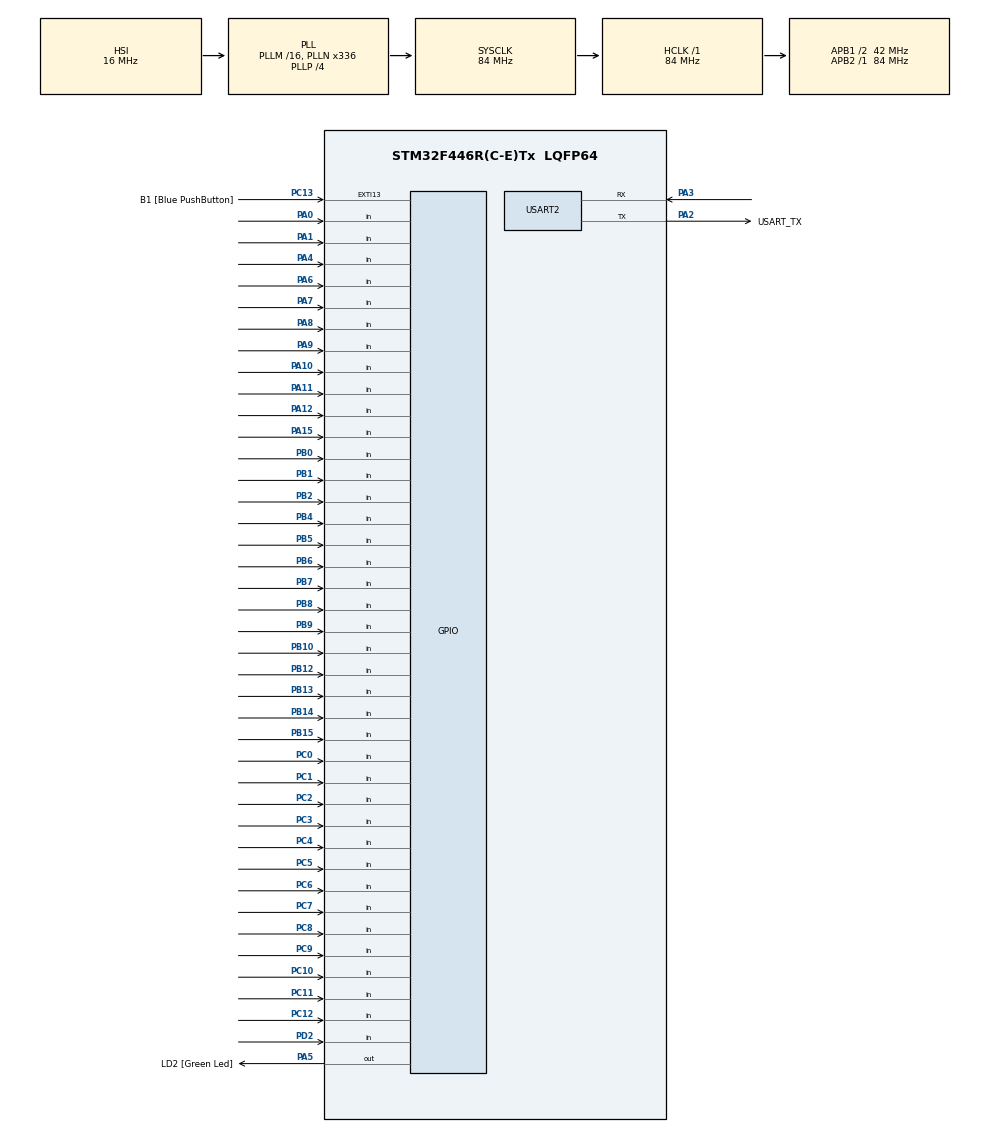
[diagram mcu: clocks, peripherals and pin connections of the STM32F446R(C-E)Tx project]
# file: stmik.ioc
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Mcu.Family=STM32F4
Mcu.Name=STM32F446R(C-E)Tx
Mcu.Package=LQFP64
NVIC.PriorityGroup=NVIC_PRIORITYGROUP_0
NVIC.USART2_IRQn=true\:0\:0\:false\:false\:true\:true\:true
PA0-WKUP.Signal=GPIO_Input
PA1.Signal=GPIO_Input
PA10.Signal=GPIO_Input
PA11.Signal=GPIO_Input
PA12.Signal=GPIO_Input
PA13.GPIO_Label=TMS
PA13.Signal=SYS_JTMS-SWDIO
PA14.GPIO_Label=TCK
PA14.Signal=SYS_JTCK-SWCLK
PA15.Signal=GPIO_Input
PA2.GPIO_Label=USART_TX
PA2.Mode=Asynchronous
PA2.Signal=USART2_TX
PA3.Mode=Asynchronous
PA3.Signal=USART2_RX
PA4.Signal=GPIO_Input
PA5.GPIO_Label=LD2 [Green Led]
PA5.Signal=GPIO_Output
PA6.Signal=GPIO_Input
PA7.Signal=GPIO_Input
PA8.Signal=GPIO_Input
PA9.Signal=GPIO_Input
PB0.Signal=GPIO_Input
PB1.Signal=GPIO_Input
PB10.Signal=GPIO_Input
PB12.Signal=GPIO_Input
PB13.Signal=GPIO_Input
PB14.Signal=GPIO_Input
PB15.Signal=GPIO_Input
PB2.Signal=GPIO_Input
PB3.GPIO_Label=SWO
PB3.Signal=SYS_JTDO-SWO
PB4.Signal=GPIO_Input
PB5.Signal=GPIO_Input
PB6.Signal=GPIO_Input
PB7.Signal=GPIO_Input
PB8.Signal=GPIO_Input
PB9.Signal=GPIO_Input
PC0.Signal=GPIO_Input
PC1.Signal=GPIO_Input
PC10.Signal=GPIO_Input
PC11.Signal=GPIO_Input
PC12.Signal=GPIO_Input
PC13.GPIO_Label=B1 [Blue PushButton]
PC13.GPIO_ModeDefaultEXTI=GPIO_MODE_IT_FALLING
PC13.Signal=GPXTI13
PC14-OSC32_IN.Signal=RCC_OSC32_IN
PC15-OSC32_OUT.Signal=RCC_OSC32_OUT
PC2.Signal=GPIO_Input
PC3.Signal=GPIO_Input
PC4.Signal=GPIO_Input
PC5.Signal=GPIO_Input
PC6.Signal=GPIO_Input
PC7.Signal=GPIO_Input
PC8.Signal=GPIO_Input
PC9.Signal=GPIO_Input
PD2.Signal=GPIO_Input
PH0-OSC_IN.Signal=RCC_OSC_IN
PH1-OSC_OUT.Signal=RCC_OSC_OUT
ProjectManager.HeapSize=0x200
ProjectManager.StackSize=0x400
ProjectManager.TargetToolchain=STM32CubeIDE
RCC.AHBFreq_Value=84000000
RCC.APB1CLKDivider=RCC_HCLK_DIV2
RCC.APB1Freq_Value=42000000
RCC.APB1TimFreq_Value=84000000
RCC.APB2Freq_Value=84000000
RCC.APB2TimFreq_Value=84000000
RCC.CortexFreq_Value=84000000
RCC.FLatency-AdvancedSettings=FLASH_LATENCY_2
RCC.HCLKFreq_Value=84000000
RCC.HSE_VALUE=8000000
RCC.HSI_VALUE=16000000
RCC.LSE_VALUE=32768
RCC.PLLN=336
RCC.PLLP=RCC_PLLP_DIV4
RCC.SYSCLKFreq_VALUE=84000000
RCC.SYSCLKSource=RCC_SYSCLKSOURCE_PLLCLK
RCC.USBFreq_Value=168000000
RCC.VCOOutputFreq_Value=336000000
USART2.VirtualMode=VM_ASYNC
board=NUCLEO-F446RE

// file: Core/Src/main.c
/* USER CODE BEGIN Header */
/**
  ******************************************************************************
  * @file           : main.c
  * @brief          : Main program body
  ******************************************************************************
  * @attention
  *
  * <h2><center>&copy; Copyright (c) 2021 STMicroelectronics.
  * All rights reserved.</center></h2>
  *
  * This software component is licensed by ST under BSD 3-Clause license,
  * the "License"; You may not use this file except in compliance with the
  * License. You may obtain a copy of the License at:
  *                        opensource.org/licenses/BSD-3-Clause
  *
  ******************************************************************************
  */
/* USER CODE END Header */
#include "main.h"
#include "usart.h"
#include "gpio.h"

/* USER CODE BEGIN Includes */
#include "receive.h"
#include "send.h"
#include "gpio.h"
#include "readA.h"
#include <string.h>
/* USER CODE END Includes */

/* USER CODE BEGIN PV */
//uint8_t buffer[4] = "hej3";
uint8_t Rx_data[4];
uint8_t Tx_data[4];
char str;

/* USER CODE END PV */

void SystemClock_Config(void);
/* USER CODE BEGIN PFP */

//static UART_HandleTypeDef s_UARTHandle = UART_HandleTypeDef();
/* USER CODE END PFP */

int main(void)
{
  /* USER CODE BEGIN 1 */
//receive();
//send();
  /* USER CODE END 1 */

  /* MCU Configuration--------------------------------------------------------*/

  /* Reset of all peripherals, Initializes the Flash interface and the Systick. */
  HAL_Init();

  /* USER CODE BEGIN Init */

  void HAL_UART_RxCpltCallback(UART_HandleTypeDef *huart)
  {
    HAL_UART_Receive_IT(&huart2, Rx_data, 4);
  }

  /* USER CODE END Init */

  /* Configure the system clock */
  SystemClock_Config();

  /* Initialize all configured peripherals */
  MX_GPIO_Init();
  MX_USART2_UART_Init();

  /* Infinite loop */
  /* USER CODE BEGIN WHILE */
  while (1)
  {
	  receive();
	  //HAL_UART_Transmit(&huart2, "hej5", 4, 100);
	  //send();
	  HAL_GPIO_TogglePin(LD2_GPIO_Port, LD2_Pin);
	  		HAL_Delay(100);
    /* USER CODE END WHILE */

  }
}

void SystemClock_Config(void)
{
  RCC_OscInitTypeDef RCC_OscInitStruct = {0};
  RCC_ClkInitTypeDef RCC_ClkInitStruct = {0};

  /** Configure the main internal regulator output voltage
  */
  __HAL_RCC_PWR_CLK_ENABLE();
  __HAL_PWR_VOLTAGESCALING_CONFIG(PWR_REGULATOR_VOLTAGE_SCALE3);
  /** Initializes the RCC Oscillators according to the specified parameters
  * in the RCC_OscInitTypeDef structure.
  */
  RCC_OscInitStruct.OscillatorType = RCC_OSCILLATORTYPE_HSI;
  RCC_OscInitStruct.HSIState = RCC_HSI_ON;
  RCC_OscInitStruct.HSICalibrationValue = RCC_HSICALIBRATION_DEFAULT;
  RCC_OscInitStruct.PLL.PLLState = RCC_PLL_ON;
  RCC_OscInitStruct.PLL.PLLSource = RCC_PLLSOURCE_HSI;
  RCC_OscInitStruct.PLL.PLLM = 16;
  RCC_OscInitStruct.PLL.PLLN = 336;
  RCC_OscInitStruct.PLL.PLLP = RCC_PLLP_DIV4;
  RCC_OscInitStruct.PLL.PLLQ = 2;
  RCC_OscInitStruct.PLL.PLLR = 2;
  if (HAL_RCC_OscConfig(&RCC_OscInitStruct) != HAL_OK)
  {
    Error_Handler();
  }
  /** Initializes the CPU, AHB and APB buses clocks
  */
  RCC_ClkInitStruct.ClockType = RCC_CLOCKTYPE_HCLK|RCC_CLOCKTYPE_SYSCLK
                              |RCC_CLOCKTYPE_PCLK1|RCC_CLOCKTYPE_PCLK2;
  RCC_ClkInitStruct.SYSCLKSource = RCC_SYSCLKSOURCE_PLLCLK;
  RCC_ClkInitStruct.AHBCLKDivider = RCC_SYSCLK_DIV1;
  RCC_ClkInitStruct.APB1CLKDivider = RCC_HCLK_DIV2;
  RCC_ClkInitStruct.APB2CLKDivider = RCC_HCLK_DIV1;

  if (HAL_RCC_ClockConfig(&RCC_ClkInitStruct, FLASH_LATENCY_2) != HAL_OK)
  {
    Error_Handler();
  }
}

void Error_Handler(void)
{
  __disable_irq();
  while (1)
  {
  }
}

/************************ (C) COPYRIGHT STMicroelectronics *****END OF FILE****/
